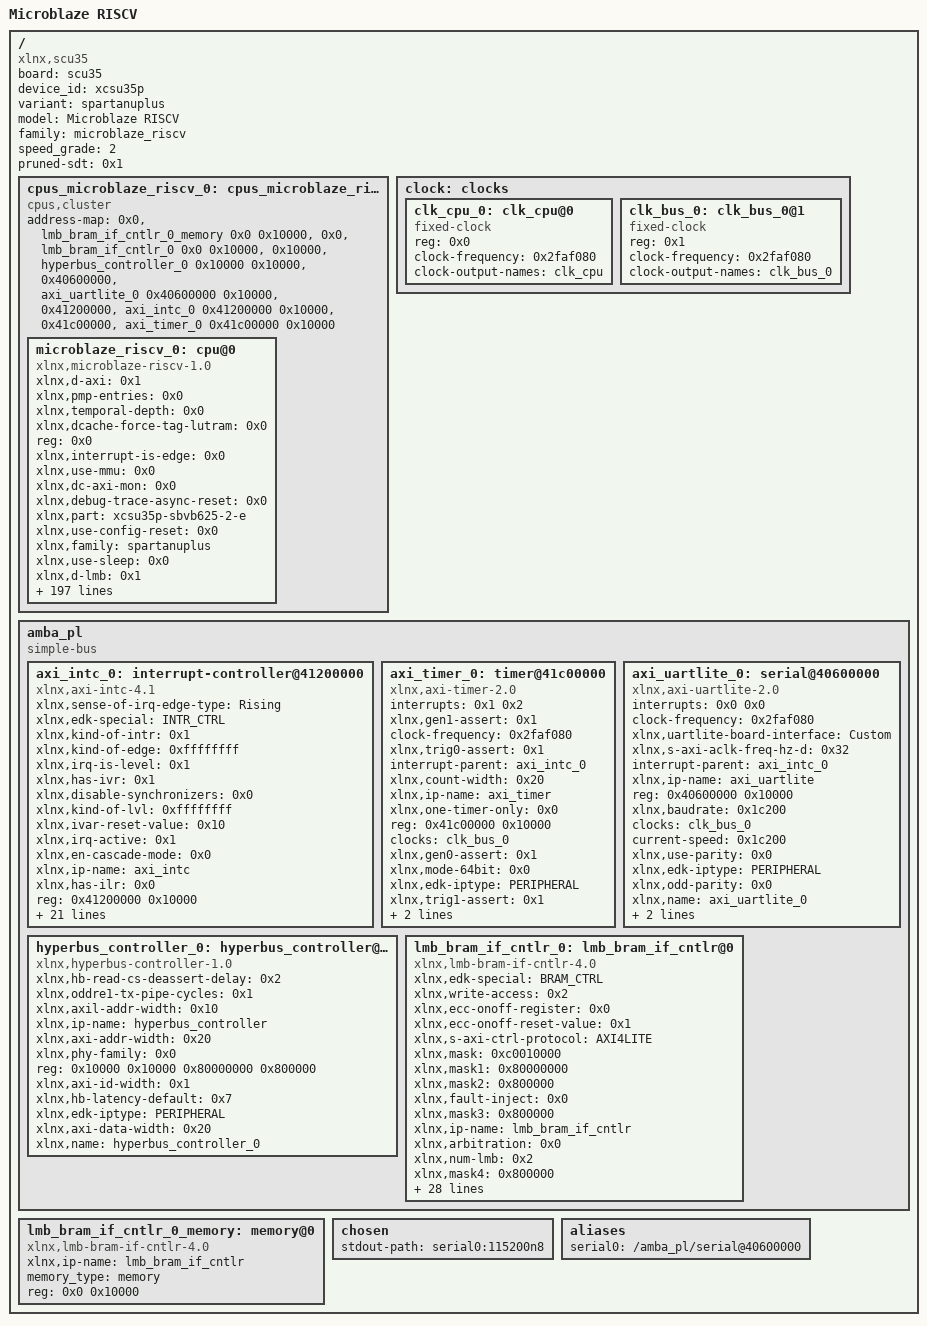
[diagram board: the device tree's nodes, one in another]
/dts-v1/;
/ {
        board = "scu35";
        compatible = "xlnx,scu35";
        device_id = "xcsu35p";
        #address-cells = <0x1>;
        variant = "spartanuplus";
        model = "Microblaze RISCV";
        #size-cells = <0x1>;
        family = "microblaze_riscv";
        speed_grade = "2";
        pruned-sdt = <0x1>;

        cpus_microblaze_riscv_0: cpus_microblaze_riscv@0 {
                phandle = <0x9>;
                #cpu-mask-cells = <0x1>;
                compatible = "cpus,cluster";
                #address-cells = <0x1>;
                #size-cells = <0x0>;
                address-map = <0x0 &lmb_bram_if_cntlr_0_memory 0x0 0x10000>,
                 <0x0 &lmb_bram_if_cntlr_0 0x0 0x10000>,
                 <0x10000 &hyperbus_controller_0 0x10000 0x10000>,
                 <0x40600000 &axi_uartlite_0 0x40600000 0x10000>,
                 <0x41200000 &axi_intc_0 0x41200000 0x10000>,
                 <0x41c00000 &axi_timer_0 0x41c00000 0x10000>;
                #ranges-address-cells = <0x1>;
                #ranges-size-cells = <0x1>;

                microblaze_riscv_0: cpu@0 {
                        phandle = <0xa>;
                        xlnx,d-axi = <0x1>;
                        xlnx,pmp-entries = <0x0>;
                        xlnx,temporal-depth = <0x0>;
                        xlnx,dcache-force-tag-lutram = <0x0>;
                        reg = <0x0>;
                        xlnx,interrupt-is-edge = <0x0>;
                        xlnx,use-mmu = <0x0>;
                        xlnx,dc-axi-mon = <0x0>;
                        xlnx,debug-trace-async-reset = <0x0>;
                        xlnx,part = "xcsu35p-sbvb625-2-e";
                        xlnx,use-config-reset = <0x0>;
                        xlnx,family = "spartanuplus";
                        xlnx,use-sleep = <0x0>;
                        xlnx,d-lmb = <0x1>;
                        xlnx,enable-discrete-ports = <0x0>;
                        xlnx,debug-interface = <0x0>;
                        xlnx,use-ext-brk = <0x0>;
                        xlnx,debug-enabled = <0x1>;
                        xlnx,daddr-size = <0x20>;
                        xlnx,use-extended-fsl-instr = <0x0>;
                        xlnx,branch-target-cache-size = <0x0>;
                        bus-handle = <&amba_pl>;
                        xlnx,pmp-addr0 = <0x0>;
                        xlnx,pmp-addr1 = <0x0>;
                        xlnx,pmp-addr2 = <0x0>;
                        xlnx,pmp-addr3 = <0x0>;
                        xlnx,pmp-addr4 = <0x0>;
                        xlnx,edk-special = "microblaze_riscv";
                        xlnx,use-dcache = <0x1>;
                        xlnx,pmp-addr5 = <0x0>;
                        xlnx,use-muldiv = <0x2>;
                        xlnx,pmp-addr6 = <0x0>;
                        xlnx,use-axi-dp-ext-addr = <0x0>;
                        xlnx,pmp-addr7 = <0x0>;
                        xlnx,pmp-addr8 = <0x0>;
                        xlnx,pmp-addr9 = <0x0>;
                        xlnx,i-axi = <0x0>;
                        xlnx,icache-streams = <0x0>;
                        xlnx,i-lmb-has-prot = <0x0>;
                        xlnx,num-sync-ff-dbg-clk = <0x1>;
                        xlnx,icache-byte-size = <0x1000>;
                        xlnx,pmp-addr10 = <0x0>;
                        d-cache-size = <0x1000>;
                        xlnx,pmp-addr11 = <0x0>;
                        xlnx,pmp-addr12 = <0x0>;
                        xlnx,pmp-addr13 = <0x0>;
                        xlnx,pmp-addr14 = <0x0>;
                        xlnx,pmp-addr15 = <0x0>;
                        xlnx,avoid-primitives = <0x0>;
                        xlnx,pmp-addr16 = <0x0>;
                        xlnx,pmp-addr17 = <0x0>;
                        xlnx,pmp-addr18 = <0x0>;
                        xlnx,pdaddr-size = <0x20>;
                        xlnx,pmp-addr19 = <0x0>;
                        xlnx,pmp-addr20 = <0x0>;
                        xlnx,pmp-addr21 = <0x0>;
                        xlnx,i-lmb = <0x1>;
                        xlnx,pmp-addr22 = <0x0>;
                        xlnx,lmb-data-size = <0x20>;
                        xlnx,lockstep-select = <0x0>;
                        xlnx,pmp-addr23 = <0x0>;
                        timebase-frequency = <0x2faf080>;
                        xlnx,pmp-addr24 = <0x0>;
                        xlnx,dcache-data-width = <0x0>;
                        xlnx,icache-force-tag-lutram = <0x0>;
                        xlnx,pmp-addr25 = <0x0>;
                        xlnx,pmp-addr26 = <0x0>;
                        xlnx,use-branch-target-cache = <0x0>;
                        xlnx,pmp-addr27 = <0x0>;
                        xlnx,number-of-pc-brk = <0x1>;
                        xlnx,pmp-addr28 = <0x0>;
                        xlnx,imprecise-exceptions = <0x0>;
                        xlnx,pmp-addr29 = <0x0>;
                        xlnx,pmp-addr30 = <0x0>;
                        xlnx,pmp-addr31 = <0x0>;
                        xlnx,pmp-addr32 = <0x0>;
                        model = "microblaze_riscv,1.0";
                        xlnx,pmp-addr33 = <0x0>;
                        xlnx,pmp-addr34 = <0x0>;
                        xlnx,pmp-addr35 = <0x0>;
                        xlnx,pmp-addr36 = <0x0>;
                        d-cache-highaddr = <0x807fffff>;
                        xlnx,optimization = <0x1>;
                        xlnx,pmp-addr37 = <0x0>;
                        xlnx,pmp-addr38 = <0x0>;
                        xlnx,pmp-addr39 = <0x0>;
                        xlnx,pmp-addr40 = <0x0>;
                        xlnx,pmp-addr41 = <0x0>;
                        xlnx,d-lmb-mon = <0x0>;
                        xlnx,pmp-addr42 = <0x0>;
                        xlnx,pmp-addr43 = <0x0>;
                        xlnx,pmp-addr44 = <0x0>;
                        xlnx,pmp-addr45 = <0x0>;
                        xlnx,pmp-addr46 = <0x0>;
                        xlnx,pmp-addr47 = <0x0>;
                        xlnx,pmp-addr48 = <0x0>;
                        xlnx,fault-tolerant = <0x0>;
                        xlnx,pmp-addr49 = <0x0>;
                        xlnx,pmp-addr50 = <0x0>;
                        xlnx,pmp-addr51 = <0x0>;
                        xlnx,pmp-enhancements = <0x0>;
                        d-cache-line-size = <0x10>;
                        xlnx,mmu-privileged-instr = <0x0>;
                        xlnx,pmp-addr52 = <0x0>;
                        clock-frequency = <0x2faf080>;
                        xlnx,pmp-addr53 = <0x0>;
                        xlnx,pmp-addr54 = <0x0>;
                        xlnx,pmp-addr55 = <0x0>;
                        xlnx,i-lmb-protocol = <0x0>;
                        xlnx,pmp-addr56 = <0x0>;
                        xlnx,pmp-addr57 = <0x0>;
                        xlnx,dp-axi-mon = <0x0>;
                        xlnx,pmp-addr58 = <0x0>;
                        xlnx,pmp-addr59 = <0x0>;
                        xlnx,pmp-addr60 = <0x0>;
                        xlnx,pmp-addr61 = <0x0>;
                        xlnx,pmp-addr62 = <0x0>;
                        xlnx,pmp-addr63 = <0x0>;
                        xlnx,debug-external-trace = <0x0>;
                        xlnx,addr-size = <0x20>;
                        xlnx,debug-num-progbuf = <0x2>;
                        xlnx,debug-event-counters = <0x0>;
                        xlnx,edk-iptype = "PROCESSOR";
                        xlnx,debug-latency-counters = <0x0>;
                        xlnx,interconnect = <0x2>;
                        xlnx,edge-is-positive = <0x1>;
                        xlnx,use-icache = <0x1>;
                        xlnx,async-wakeup = <0x3>;
                        xlnx,s-axi = <0x0>;
                        xlnx,use-ext-nm-brk = <0x0>;
                        xlnx,ic-axi-mon = <0x0>;
                        xlnx,archid = <0x1>;
                        xlnx,num-sync-ff-clk-irq = <0x1>;
                        xlnx,freq = <0x2faf080>;
                        xlnx,lockstep-master = <0x0>;
                        xlnx,pmp-cfg0 = <0x0>;
                        xlnx,pmp-cfg1 = <0x0>;
                        xlnx,iaddr-size = <0x20>;
                        xlnx,interrupt-mon = <0x0>;
                        xlnx,pmp-cfg2 = <0x0>;
                        xlnx,number-of-wr-addr-brk = <0x0>;
                        xlnx,pmp-cfg3 = <0x0>;
                        xlnx,pmp-cfg4 = <0x0>;
                        xlnx,use-interrupt = <0x1>;
                        xlnx,pmp-cfg5 = <0x0>;
                        xlnx,async-interrupt = <0x1>;
                        xlnx,pc-width = <0x10>;
                        xlnx,pmp-cfg6 = <0x0>;
                        xlnx,icache-victims = <0x0>;
                        xlnx,pmp-cfg7 = <0x0>;
                        xlnx,pmp-cfg8 = <0x0>;
                        xlnx,pmp-cfg9 = <0x0>;
                        xlnx,use-bitman-a = <0x1>;
                        xlnx,use-bitman-b = <0x1>;
                        xlnx,use-bitman-c = <0x1>;
                        xlnx,i-lmb-mon = <0x0>;
                        xlnx,dcache-byte-size = <0x1000>;
                        xlnx,data-size = <0x20>;
                        compatible = "xlnx,microblaze-riscv-1.0", "xlnx,microblaze_riscv";
                        xlnx,pmp-debug-inhibit = <0x0>;
                        xlnx,use-sstc = <0x1>;
                        xlnx,fsl-exception = <0x0>;
                        xlnx,dcache-use-writeback = <0x0>;
                        device_type = "cpu";
                        xlnx,impid = <0x1>;
                        xlnx,use-bitman-s = <0x1>;
                        xlnx,base-vectors = <0x0>;
                        xlnx,icache-line-len = <0x4>;
                        xlnx,d-lmb-has-prot = <0x0>;
                        xlnx,use-barrel = <0x1>;
                        xlnx,misaligned-exceptions = <0x1>;
                        xlnx,piaddr-size = <0x20>;
                        xlnx,use-bitman = <0xf>;
                        xlnx,dcache-line-len = <0x4>;
                        xlnx,num-sync-ff-clk = <0x2>;
                        xlnx,memory-ip-list = "lmb_bram_if_cntlr_0_memory", "lmb_bram_if_cntlr_0_memory";
                        xlnx,number-of-rd-addr-brk = <0x0>;
                        xlnx,use-counters = <0x1>;
                        xlnx,lockstep-slave = <0x0>;
                        interrupt-handle = <&axi_intc_0>;
                        xlnx,pmp-cfg10 = <0x0>;
                        xlnx,pmp-cfg11 = <0x0>;
                        xlnx,debug-profile-size = <0x0>;
                        xlnx,pmp-cfg12 = <0x0>;
                        xlnx,pmp-cfg13 = <0x0>;
                        xlnx,pmp-cfg14 = <0x0>;
                        xlnx,pmp-cfg15 = <0x0>;
                        xlnx,debug-counter-width = <0x40>;
                        xlnx,icache-data-width = <0x0>;
                        xlnx,ip-name = "microblaze_riscv";
                        xlnx,ip-axi-mon = <0x0>;
                        xlnx,d-lmb-protocol = <0x0>;
                        xlnx,trace = <0x0>;
                        xlnx,ill-instr-exception = <0x1>;
                        xlnx,debug-trace-size = <0x0>;
                        xlnx,pmp-granularity = <0x2>;
                        xlnx,num-sync-ff-dbg-trace-clk = <0x2>;
                        xlnx,ecc-use-ce-exception = <0x0>;
                        xlnx,num-sync-ff-clk-debug = <0x2>;
                        xlnx,use-atomic = <0x1>;
                        xlnx,g-template-list = <0x1>;
                        xlnx,trap-enhancement = <0x0>;
                        xlnx,hartid = <0x0>;
                        xlnx,use-fpu = <0x0>;
                        xlnx,use-non-secure = <0x0>;
                        d-cache-baseaddr = <0x80000000>;
                        xlnx,use-compression = <0x1>;
                        xlnx,instr-size = <0x20>;
                        xlnx,fsl-links = <0x0>;
                        xlnx,dcache-victims = <0x0>;
                        xlnx,pmp-read-only = <0x0>;
                };
        };

        clock: clocks {
                phandle = <0xb>;
                #address-cells = <0x1>;
                #size-cells = <0x0>;

                clk_cpu_0: clk_cpu@0 {
                        phandle = <0xc>;
                        compatible = "fixed-clock";
                        reg = <0x0>;
                        clock-frequency = <0x2faf080>;
                        clock-output-names = "clk_cpu";
                        #clock-cells = <0x0>;
                };

                clk_bus_0: clk_bus_0@1 {
                        phandle = <0x8>;
                        compatible = "fixed-clock";
                        reg = <0x1>;
                        clock-frequency = <0x2faf080>;
                        clock-output-names = "clk_bus_0";
                        #clock-cells = <0x0>;
                };
        };

        amba_pl: amba_pl {
                phandle = <0x7>;
                ranges;
                compatible = "simple-bus";
                #address-cells = <0x1>;
                #size-cells = <0x1>;

                axi_intc_0: interrupt-controller@41200000 {
                        phandle = <0x5>;
                        #interrupt-cells = <0x2>;
                        xlnx,sense-of-irq-edge-type = "Rising";
                        xlnx,edk-special = "INTR_CTRL";
                        xlnx,kind-of-intr = <0x1>;
                        xlnx,kind-of-edge = <0xffffffff>;
                        xlnx,irq-is-level = <0x1>;
                        xlnx,has-ivr = <0x1>;
                        compatible = "xlnx,axi-intc-4.1", "xlnx,xps-intc-1.00.a";
                        xlnx,disable-synchronizers = <0x0>;
                        xlnx,kind-of-lvl = <0xffffffff>;
                        xlnx,ivar-reset-value = <0x10>;
                        xlnx,irq-active = <0x1>;
                        xlnx,en-cascade-mode = <0x0>;
                        xlnx,ip-name = "axi_intc";
                        xlnx,has-ilr = <0x0>;
                        reg = <0x41200000 0x10000>;
                        xlnx,addr-width = <0x20>;
                        xlnx,s-axi-aclk-freq-mhz = <0x32>;
                        xlnx,num-sw-intr = <0x0>;
                        xlnx,irq-connection = <0x0>;
                        xlnx,num-intr-inputs = <0x2>;
                        xlnx,has-sie = <0x1>;
                        xlnx,enable-async = <0x0>;
                        xlnx,has-cie = <0x1>;
                        xlnx,num-sync-ff = <0x2>;
                        xlnx,edk-iptype = "PERIPHERAL";
                        xlnx,mb-clk-not-connected = <0x1>;
                        xlnx,has-ipr = <0x1>;
                        xlnx,sense-of-irq-level-type = "Active_High";
                        xlnx,cascade-master = <0x0>;
                        xlnx,processor-clk-freq-mhz = <0x64>;
                        status = "okay";
                        xlnx,is-fast = <0x0>;
                        xlnx,has-fast = <0x0>;
                        xlnx,ivar-rst-val = <0x10>;
                        interrupt-controller;
                        xlnx,async-intr = <0xfffffffc>;
                        xlnx,name = "axi_intc_0";
                };

                axi_timer_0: timer@41c00000 {
                        phandle = <0x6>;
                        interrupts = <0x1 0x2>;
                        compatible = "xlnx,axi-timer-2.0", "xlnx,xps-timer-1.00.a";
                        xlnx,gen1-assert = <0x1>;
                        clock-frequency = <0x2faf080>;
                        xlnx,trig0-assert = <0x1>;
                        interrupt-parent = <&axi_intc_0>;
                        xlnx,count-width = <0x20>;
                        xlnx,ip-name = "axi_timer";
                        xlnx,one-timer-only = <0x0>;
                        reg = <0x41c00000 0x10000>;
                        clocks = <&clk_bus_0>;
                        xlnx,gen0-assert = <0x1>;
                        xlnx,mode-64bit = <0x0>;
                        xlnx,edk-iptype = "PERIPHERAL";
                        status = "okay";
                        xlnx,trig1-assert = <0x1>;
                        xlnx,enable-timer2 = <0x1>;
                        interrupt-names = "interrupt";
                        xlnx,name = "axi_timer_0";
                };

                axi_uartlite_0: serial@40600000 {
                        phandle = <0x4>;
                        interrupts = <0x0 0x0>;
                        compatible = "xlnx,axi-uartlite-2.0", "xlnx,xps-uartlite-1.00.a";
                        clock-frequency = <0x2faf080>;
                        xlnx,uartlite-board-interface = "Custom";
                        xlnx,s-axi-aclk-freq-hz-d = <0x32>;
                        interrupt-parent = <&axi_intc_0>;
                        xlnx,ip-name = "axi_uartlite";
                        reg = <0x40600000 0x10000>;
                        xlnx,baudrate = <0x1c200>;
                        clocks = <&clk_bus_0>;
                        current-speed = <0x1c200>;
                        xlnx,use-parity = <0x0>;
                        xlnx,edk-iptype = "PERIPHERAL";
                        xlnx,odd-parity = <0x0>;
                        status = "okay";
                        interrupt-names = "interrupt";
                        xlnx,name = "axi_uartlite_0";
                        xlnx,data-bits = <0x8>;
                        xlnx,parity = "No_Parity";
                };

                hyperbus_controller_0: hyperbus_controller@10000 {
                        phandle = <0x3>;
                        compatible = "xlnx,hyperbus-controller-1.0";
                        xlnx,hb-read-cs-deassert-delay = <0x2>;
                        xlnx,oddre1-tx-pipe-cycles = <0x1>;
                        xlnx,axil-addr-width = <0x10>;
                        xlnx,ip-name = "hyperbus_controller";
                        xlnx,axi-addr-width = <0x20>;
                        xlnx,phy-family = <0x0>;
                        reg = <0x10000 0x10000 0x80000000 0x800000>;
                        xlnx,axi-id-width = <0x1>;
                        xlnx,hb-latency-default = <0x7>;
                        xlnx,edk-iptype = "PERIPHERAL";
                        status = "okay";
                        xlnx,axi-data-width = <0x20>;
                        xlnx,name = "hyperbus_controller_0";
                };

                lmb_bram_if_cntlr_0: lmb_bram_if_cntlr@0 {
                        phandle = <0x2>;
                        xlnx,edk-special = "BRAM_CTRL";
                        xlnx,write-access = <0x2>;
                        compatible = "xlnx,lmb-bram-if-cntlr-4.0", "xlnx,axi-bram-ctrl";
                        xlnx,ecc-onoff-register = <0x0>;
                        xlnx,ecc-onoff-reset-value = <0x1>;
                        xlnx,s-axi-ctrl-protocol = "AXI4LITE";
                        xlnx,mask = <0xc0010000>;
                        xlnx,mask1 = <0x80000000>;
                        xlnx,mask2 = <0x800000>;
                        xlnx,fault-inject = <0x0>;
                        xlnx,mask3 = <0x800000>;
                        xlnx,ip-name = "lmb_bram_if_cntlr";
                        xlnx,arbitration = <0x0>;
                        xlnx,num-lmb = <0x2>;
                        xlnx,mask4 = <0x800000>;
                        reg = <0x0 0x10000>;
                        xlnx,s-axi-ctrl-addr-width = <0x20>;
                        xlnx,mask5 = <0x800000>;
                        xlnx,ecc-status-registers = <0x0>;
                        xlnx,prot-cfg = <0xff>;
                        xlnx,mask6 = <0x800000>;
                        xlnx,lmb-protocol = <0x0>;
                        xlnx,ce-counter-width = <0x0>;
                        xlnx,prot-cfg1 = <0xff>;
                        xlnx,mask7 = <0x800000>;
                        xlnx,ecc = <0x0>;
                        xlnx,edk-iptype = "PERIPHERAL";
                        xlnx,prot-cfg2 = <0xff>;
                        xlnx,lmb-dwidth = <0x20>;
                        xlnx,interconnect = <0x0>;
                        xlnx,ce-failing-registers = <0x0>;
                        xlnx,prot-cfg3 = <0xff>;
                        xlnx,ue-failing-registers = <0x0>;
                        xlnx,prot-cfg4 = <0xff>;
                        xlnx,lmb-has-prot = <0x0>;
                        status = "okay";
                        xlnx,data-width = <0x20>;
                        xlnx,prot-cfg5 = <0xff>;
                        xlnx,s-axi-ctrl-data-width = <0x20>;
                        xlnx,prot-cfg6 = <0xff>;
                        xlnx,bram-awidth = <0x20>;
                        xlnx,prot-cfg7 = <0xff>;
                        xlnx,lmb-awidth = <0x20>;
                        xlnx,name = "lmb_bram_if_cntlr_0";
                };
        };

        lmb_bram_if_cntlr_0_memory: memory@0 {
                phandle = <0x1>;
                compatible = "xlnx,lmb-bram-if-cntlr-4.0";
                xlnx,ip-name = "lmb_bram_if_cntlr";
                device_type = "memory";
                memory_type = "memory";
                reg = <0x0 0x10000>;
        };

        chosen {
                stdout-path = "serial0:115200n8";
        };

        aliases {
                serial0 = "/amba_pl/serial@40600000";
        };

        __symbols__ {
                cpus_microblaze_riscv_0 = "/cpus_microblaze_riscv@0";
                microblaze_riscv_0 = "/cpus_microblaze_riscv@0/cpu@0";
                clock = "/clocks";
                clk_cpu_0 = "/clocks/clk_cpu@0";
                clk_bus_0 = "/clocks/clk_bus_0@1";
                amba_pl = "/amba_pl";
                axi_intc_0 = "/amba_pl/interrupt-controller@41200000";
                axi_timer_0 = "/amba_pl/timer@41c00000";
                axi_uartlite_0 = "/amba_pl/serial@40600000";
                hyperbus_controller_0 = "/amba_pl/hyperbus_controller@10000";
                lmb_bram_if_cntlr_0 = "/amba_pl/lmb_bram_if_cntlr@0";
                lmb_bram_if_cntlr_0_memory = "/memory@0";
        };
};
